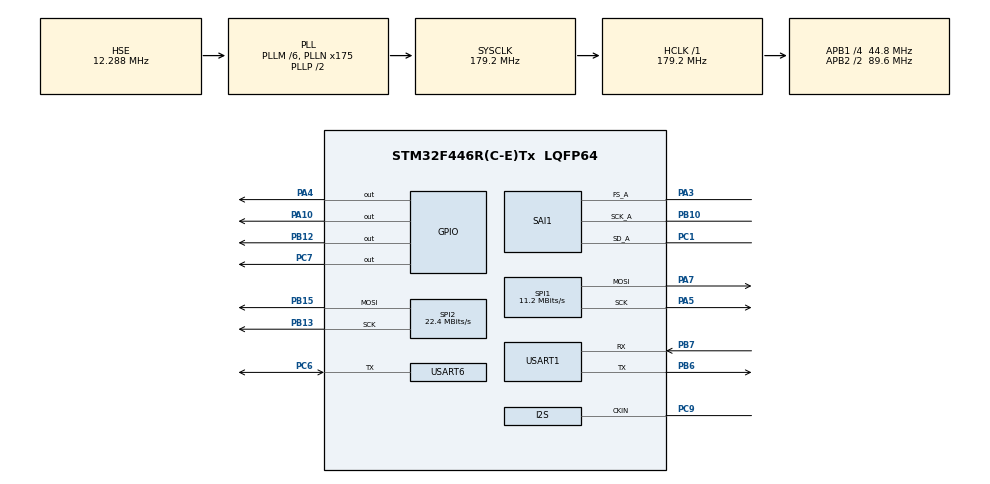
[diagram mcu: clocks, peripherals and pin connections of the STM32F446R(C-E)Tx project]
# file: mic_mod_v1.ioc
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Dma.Request0=SPI2_TX
Dma.Request1=SPI1_TX
Dma.SPI1_TX.1.Direction=DMA_MEMORY_TO_PERIPH
Dma.SPI1_TX.1.FIFOMode=DMA_FIFOMODE_DISABLE
Dma.SPI1_TX.1.Instance=DMA2_Stream3
Dma.SPI1_TX.1.MemDataAlignment=DMA_MDATAALIGN_HALFWORD
Dma.SPI1_TX.1.MemInc=DMA_MINC_ENABLE
Dma.SPI1_TX.1.Mode=DMA_CIRCULAR
Dma.SPI1_TX.1.PeriphDataAlignment=DMA_PDATAALIGN_HALFWORD
Dma.SPI1_TX.1.PeriphInc=DMA_PINC_DISABLE
Dma.SPI1_TX.1.Priority=DMA_PRIORITY_MEDIUM
Dma.SPI2_TX.0.Direction=DMA_MEMORY_TO_PERIPH
Dma.SPI2_TX.0.FIFOMode=DMA_FIFOMODE_DISABLE
Dma.SPI2_TX.0.Instance=DMA1_Stream4
Dma.SPI2_TX.0.MemDataAlignment=DMA_MDATAALIGN_HALFWORD
Dma.SPI2_TX.0.MemInc=DMA_MINC_ENABLE
Dma.SPI2_TX.0.Mode=DMA_CIRCULAR
Dma.SPI2_TX.0.PeriphDataAlignment=DMA_PDATAALIGN_HALFWORD
Dma.SPI2_TX.0.PeriphInc=DMA_PINC_DISABLE
Dma.SPI2_TX.0.Priority=DMA_PRIORITY_MEDIUM
Mcu.Family=STM32F4
Mcu.Name=STM32F446R(C-E)Tx
Mcu.Package=LQFP64
NVIC.DMA1_Stream4_IRQn=true\:0\:0\:false\:false\:true\:false
NVIC.DMA2_Stream3_IRQn=true\:0\:0\:false\:false\:true\:false
NVIC.PriorityGroup=NVIC_PRIORITYGROUP_4
PA10.Signal=GPIO_Output
PA3.Mode=SAI_A_Master
PA3.Signal=SAI1_FS_A
PA4.Signal=GPIO_Output
PA5.Mode=TX_Only_Simplex_Unidirect_Master
PA5.Signal=SPI1_SCK
PA7.Mode=TX_Only_Simplex_Unidirect_Master
PA7.Signal=SPI1_MOSI
PB10.Mode=SAI_A_Master
PB10.Signal=SAI1_SCK_A
PB12.Signal=GPIO_Output
PB13.Mode=TX_Only_Simplex_Unidirect_Master
PB13.Signal=SPI2_SCK
PB15.Mode=TX_Only_Simplex_Unidirect_Master
PB15.Signal=SPI2_MOSI
PB6.Mode=Asynchronous
PB6.Signal=USART1_TX
PB7.Mode=Asynchronous
PB7.Signal=USART1_RX
PC1.Mode=SAI_A_Master
PC1.Signal=SAI1_SD_A
PC6.Mode=Half_duplex(single_wire_mode)
PC6.Signal=USART6_TX
PC7.Signal=GPIO_Output
PC9.Mode=Audio_ClockIn
PC9.Signal=I2S_CKIN
PH0-OSC_IN.Mode=HSE-External-Oscillator
PH0-OSC_IN.Signal=RCC_OSC_IN
PH1-OSC_OUT.Mode=HSE-External-Oscillator
PH1-OSC_OUT.Signal=RCC_OSC_OUT
ProjectManager.HeapSize=0x200
ProjectManager.StackSize=0x400
ProjectManager.TargetToolchain=SW4STM32
RCC.AHBFreq_Value=179200000
RCC.APB1CLKDivider=RCC_HCLK_DIV4
RCC.APB1Freq_Value=44800000
RCC.APB1TimFreq_Value=89600000
RCC.APB2CLKDivider=RCC_HCLK_DIV2
RCC.APB2Freq_Value=89600000
RCC.APB2TimFreq_Value=179200000
RCC.CortexFreq_Value=179200000
RCC.HCLKFreq_Value=179200000
RCC.HSE_VALUE=12288000
RCC.PLLM=6
RCC.PLLN=175
RCC.PLLSAIM=8
RCC.PLLSAIN=169
RCC.PLLSAIQ=8
RCC.PLLSAIQDiv=3
RCC.PLLSourceVirtual=RCC_PLLSOURCE_HSE
RCC.SAIACLockSelection=RCC_SAI1CLKSOURCE_EXT
RCC.SYSCLKFreq_VALUE=179200000
RCC.SYSCLKSource=RCC_SYSCLKSOURCE_PLLCLK
RCC.USBFreq_Value=179200000
RCC.VCOOutputFreq_Value=358400000
SAI1.Instance-SAI_A_Master=SAI$Index_Block_A
SAI1.MClockEnable-SAI_A_Master=SAI_MASTERCLOCK_DISABLE
SAI1.Synchro-SAI_A_Master=SAI_ASYNCHRONOUS
SAI1.VirtualMode-SAI_A_Master=VM_MASTER
SPI1.BaudRatePrescaler=SPI_BAUDRATEPRESCALER_8
SPI1.CalculateBaudRate=11.2 MBits/s
SPI1.DataSize=SPI_DATASIZE_16BIT
SPI1.Direction=SPI_DIRECTION_2LINES
SPI1.Mode=SPI_MODE_MASTER
SPI1.VirtualType=VM_MASTER
SPI2.BaudRatePrescaler=SPI_BAUDRATEPRESCALER_2
SPI2.CalculateBaudRate=22.4 MBits/s
SPI2.DataSize=SPI_DATASIZE_16BIT
SPI2.Direction=SPI_DIRECTION_2LINES
SPI2.Mode=SPI_MODE_MASTER
SPI2.VirtualType=VM_MASTER
USART1.VirtualMode=VM_ASYNC
USART6.VirtualMode=VM_ASYNC
board=mic_mod_v1

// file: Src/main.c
/**
  ******************************************************************************
  * @file           : main.c
  * @brief          : Main program body
  ******************************************************************************
  ** This notice applies to any and all portions of this file
  * that are not between comment pairs USER CODE BEGIN and
  * USER CODE END. Other portions of this file, whether
  * inserted by the user or by software development tools
  * are owned by their respective copyright owners.
  *
  * COPYRIGHT(c) 2018 STMicroelectronics
  *
  * Redistribution and use in source and binary forms, with or without modification,
  * are permitted provided that the following conditions are met:
  *   1. Redistributions of source code must retain the above copyright notice,
  *      this list of conditions and the following disclaimer.
  *   2. Redistributions in binary form must reproduce the above copyright notice,
  *      this list of conditions and the following disclaimer in the documentation
  *      and/or other materials provided with the distribution.
  *   3. Neither the name of STMicroelectronics nor the names of its contributors
  *      may be used to endorse or promote products derived from this software
  *      without specific prior written permission.
  *
  * THIS SOFTWARE IS PROVIDED BY THE COPYRIGHT HOLDERS AND CONTRIBUTORS "AS IS"
  * AND ANY EXPRESS OR IMPLIED WARRANTIES, INCLUDING, BUT NOT LIMITED TO, THE
  * IMPLIED WARRANTIES OF MERCHANTABILITY AND FITNESS FOR A PARTICULAR PURPOSE ARE
  * DISCLAIMED. IN NO EVENT SHALL THE COPYRIGHT HOLDER OR CONTRIBUTORS BE LIABLE
  * FOR ANY DIRECT, INDIRECT, INCIDENTAL, SPECIAL, EXEMPLARY, OR CONSEQUENTIAL
  * DAMAGES (INCLUDING, BUT NOT LIMITED TO, PROCUREMENT OF SUBSTITUTE GOODS OR
  * SERVICES; LOSS OF USE, DATA, OR PROFITS; OR BUSINESS INTERRUPTION) HOWEVER
  * CAUSED AND ON ANY THEORY OF LIABILITY, WHETHER IN CONTRACT, STRICT LIABILITY,
  * OR TORT (INCLUDING NEGLIGENCE OR OTHERWISE) ARISING IN ANY WAY OUT OF THE USE
  * OF THIS SOFTWARE, EVEN IF ADVISED OF THE POSSIBILITY OF SUCH DAMAGE.
  *
  ******************************************************************************
  */
#include "main.h"
#include "stm32f4xx_hal.h"

/* USER CODE BEGIN Includes */

#include "app.h"

/* USER CODE END Includes */

SAI_HandleTypeDef hsai_BlockA1;

SPI_HandleTypeDef hspi1;
SPI_HandleTypeDef hspi2;
DMA_HandleTypeDef hdma_spi1_tx;
DMA_HandleTypeDef hdma_spi2_tx;

UART_HandleTypeDef huart1;
UART_HandleTypeDef huart6;

/* USER CODE BEGIN PV */
/* Private variables ---------------------------------------------------------*/

/* USER CODE END PV */

void SystemClock_Config(void);
static void MX_GPIO_Init(void);
static void MX_DMA_Init(void);
static void MX_SAI1_Init(void);
static void MX_SPI1_Init(void);
static void MX_SPI2_Init(void);
static void MX_USART6_UART_Init(void);
static void MX_USART1_UART_Init(void);

/* USER CODE BEGIN PFP */
/* Private function prototypes -----------------------------------------------*/

/* USER CODE END PFP */

/* USER CODE BEGIN 0 */

#define SZ 8*48

/* USER CODE END 0 */

int main(void)
{

  /* MCU Configuration----------------------------------------------------------*/

  /* Reset of all peripherals, Initializes the Flash interface and the Systick. */
  HAL_Init();

  /* Configure the system clock */
  SystemClock_Config();

  /* Initialize all configured peripherals */
  MX_GPIO_Init();
  MX_DMA_Init();
  MX_SAI1_Init();
  MX_SPI1_Init();
  MX_SPI2_Init();
  MX_USART6_UART_Init();
  MX_USART1_UART_Init();
  /* USER CODE BEGIN 2 */

  //application();
  int16_t pack1[SZ] = {1}, pack2[SZ] = {2};
  int k;

  /* USER CODE END 2 */

  /* Infinite loop */
  /* USER CODE BEGIN WHILE */

  HAL_GPIO_WritePin (GPIOA, GPIO_PIN_4, GPIO_PIN_SET);
  HAL_GPIO_WritePin (GPIOB, GPIO_PIN_12, GPIO_PIN_SET);

  while (1)
  {

    HAL_Delay(1);
    //HAL_GPIO_WritePin(GPIOA, GPIO_PIN_4, GPIO_PIN_SET);
    HAL_GPIO_WritePin(GPIOB, GPIO_PIN_12, GPIO_PIN_SET);

    for (k=0; k<SZ; k++)
    {
      pack1[k]++;
      pack2[k]++;
    }
    //HAL_SPI_Transmit_DMA (&hspi2, (uint8_t *)pack2, sizeof(pack2));
    HAL_SPI_Transmit_DMA (&hspi1, (uint8_t *)pack1, sizeof(pack1));

    HAL_GPIO_WritePin(GPIOB, GPIO_PIN_12, GPIO_PIN_RESET);
    //HAL_GPIO_WritePin(GPIOA, GPIO_PIN_4, GPIO_PIN_RESET);
    //HAL_GPIO_WritePin(GPIOA, GPIO_PIN_4, GPIO_PIN_RESET);
  /* USER CODE END WHILE */

  }

}

void SystemClock_Config(void)
{

  RCC_OscInitTypeDef RCC_OscInitStruct;
  RCC_ClkInitTypeDef RCC_ClkInitStruct;
  RCC_PeriphCLKInitTypeDef PeriphClkInitStruct;

    /**Configure the main internal regulator output voltage
    */
  __HAL_RCC_PWR_CLK_ENABLE();

  __HAL_PWR_VOLTAGESCALING_CONFIG(PWR_REGULATOR_VOLTAGE_SCALE1);

    /**Initializes the CPU, AHB and APB busses clocks
    */
  RCC_OscInitStruct.OscillatorType = RCC_OSCILLATORTYPE_HSE;
  RCC_OscInitStruct.HSEState = RCC_HSE_ON;
  RCC_OscInitStruct.PLL.PLLState = RCC_PLL_ON;
  RCC_OscInitStruct.PLL.PLLSource = RCC_PLLSOURCE_HSE;
  RCC_OscInitStruct.PLL.PLLM = 6;
  RCC_OscInitStruct.PLL.PLLN = 175;
  RCC_OscInitStruct.PLL.PLLP = RCC_PLLP_DIV2;
  RCC_OscInitStruct.PLL.PLLQ = 2;
  RCC_OscInitStruct.PLL.PLLR = 2;
  if (HAL_RCC_OscConfig(&RCC_OscInitStruct) != HAL_OK)
  {
    _Error_Handler(__FILE__, __LINE__);
  }

    /**Activate the Over-Drive mode
    */
  if (HAL_PWREx_EnableOverDrive() != HAL_OK)
  {
    _Error_Handler(__FILE__, __LINE__);
  }

    /**Initializes the CPU, AHB and APB busses clocks
    */
  RCC_ClkInitStruct.ClockType = RCC_CLOCKTYPE_HCLK|RCC_CLOCKTYPE_SYSCLK
                              |RCC_CLOCKTYPE_PCLK1|RCC_CLOCKTYPE_PCLK2;
  RCC_ClkInitStruct.SYSCLKSource = RCC_SYSCLKSOURCE_PLLCLK;
  RCC_ClkInitStruct.AHBCLKDivider = RCC_SYSCLK_DIV1;
  RCC_ClkInitStruct.APB1CLKDivider = RCC_HCLK_DIV4;
  RCC_ClkInitStruct.APB2CLKDivider = RCC_HCLK_DIV2;

  if (HAL_RCC_ClockConfig(&RCC_ClkInitStruct, FLASH_LATENCY_5) != HAL_OK)
  {
    _Error_Handler(__FILE__, __LINE__);
  }

  PeriphClkInitStruct.PeriphClockSelection = RCC_PERIPHCLK_SAI1;
  PeriphClkInitStruct.Sai1ClockSelection = RCC_SAI1CLKSOURCE_EXT;
  if (HAL_RCCEx_PeriphCLKConfig(&PeriphClkInitStruct) != HAL_OK)
  {
    _Error_Handler(__FILE__, __LINE__);
  }

    /**Configure the Systick interrupt time
    */
  HAL_SYSTICK_Config(HAL_RCC_GetHCLKFreq()/1000);

    /**Configure the Systick
    */
  HAL_SYSTICK_CLKSourceConfig(SYSTICK_CLKSOURCE_HCLK);

  /* SysTick_IRQn interrupt configuration */
  HAL_NVIC_SetPriority(SysTick_IRQn, 0, 0);
}

/* SAI1 init function */
static void MX_SAI1_Init(void)
{

  hsai_BlockA1.Instance = SAI1_Block_A;
  hsai_BlockA1.Init.Protocol = SAI_FREE_PROTOCOL;
  hsai_BlockA1.Init.AudioMode = SAI_MODEMASTER_TX;
  hsai_BlockA1.Init.DataSize = SAI_DATASIZE_24;
  hsai_BlockA1.Init.FirstBit = SAI_FIRSTBIT_MSB;
  hsai_BlockA1.Init.ClockStrobing = SAI_CLOCKSTROBING_FALLINGEDGE;
  hsai_BlockA1.Init.Synchro = SAI_ASYNCHRONOUS;
  hsai_BlockA1.Init.OutputDrive = SAI_OUTPUTDRIVE_DISABLE;
  hsai_BlockA1.Init.NoDivider = SAI_MASTERDIVIDER_ENABLE;
  hsai_BlockA1.Init.FIFOThreshold = SAI_FIFOTHRESHOLD_EMPTY;
  hsai_BlockA1.Init.ClockSource = SAI_CLKSOURCE_NA;
  hsai_BlockA1.Init.AudioFrequency = SAI_AUDIO_FREQUENCY_192K;
  hsai_BlockA1.Init.SynchroExt = SAI_SYNCEXT_DISABLE;
  hsai_BlockA1.Init.MonoStereoMode = SAI_STEREOMODE;
  hsai_BlockA1.Init.CompandingMode = SAI_NOCOMPANDING;
  hsai_BlockA1.Init.TriState = SAI_OUTPUT_NOTRELEASED;
  hsai_BlockA1.FrameInit.FrameLength = 8;
  hsai_BlockA1.FrameInit.ActiveFrameLength = 1;
  hsai_BlockA1.FrameInit.FSDefinition = SAI_FS_STARTFRAME;
  hsai_BlockA1.FrameInit.FSPolarity = SAI_FS_ACTIVE_LOW;
  hsai_BlockA1.FrameInit.FSOffset = SAI_FS_FIRSTBIT;
  hsai_BlockA1.SlotInit.FirstBitOffset = 0;
  hsai_BlockA1.SlotInit.SlotSize = SAI_SLOTSIZE_DATASIZE;
  hsai_BlockA1.SlotInit.SlotNumber = 1;
  hsai_BlockA1.SlotInit.SlotActive = 0x00000000;
  if (HAL_SAI_Init(&hsai_BlockA1) != HAL_OK)
  {
    _Error_Handler(__FILE__, __LINE__);
  }

}

/* SPI1 init function */
static void MX_SPI1_Init(void)
{

  /* SPI1 parameter configuration*/
  hspi1.Instance = SPI1;
  hspi1.Init.Mode = SPI_MODE_MASTER;
  hspi1.Init.Direction = SPI_DIRECTION_2LINES;
  hspi1.Init.DataSize = SPI_DATASIZE_16BIT;
  hspi1.Init.CLKPolarity = SPI_POLARITY_LOW;
  hspi1.Init.CLKPhase = SPI_PHASE_1EDGE;
  hspi1.Init.NSS = SPI_NSS_SOFT;
  hspi1.Init.BaudRatePrescaler = SPI_BAUDRATEPRESCALER_8;
  hspi1.Init.FirstBit = SPI_FIRSTBIT_MSB;
  hspi1.Init.TIMode = SPI_TIMODE_DISABLE;
  hspi1.Init.CRCCalculation = SPI_CRCCALCULATION_DISABLE;
  hspi1.Init.CRCPolynomial = 10;
  if (HAL_SPI_Init(&hspi1) != HAL_OK)
  {
    _Error_Handler(__FILE__, __LINE__);
  }

}

/* SPI2 init function */
static void MX_SPI2_Init(void)
{

  /* SPI2 parameter configuration*/
  hspi2.Instance = SPI2;
  hspi2.Init.Mode = SPI_MODE_MASTER;
  hspi2.Init.Direction = SPI_DIRECTION_2LINES;
  hspi2.Init.DataSize = SPI_DATASIZE_16BIT;
  hspi2.Init.CLKPolarity = SPI_POLARITY_LOW;
  hspi2.Init.CLKPhase = SPI_PHASE_1EDGE;
  hspi2.Init.NSS = SPI_NSS_SOFT;
  hspi2.Init.BaudRatePrescaler = SPI_BAUDRATEPRESCALER_2;
  hspi2.Init.FirstBit = SPI_FIRSTBIT_MSB;
  hspi2.Init.TIMode = SPI_TIMODE_DISABLE;
  hspi2.Init.CRCCalculation = SPI_CRCCALCULATION_DISABLE;
  hspi2.Init.CRCPolynomial = 10;
  if (HAL_SPI_Init(&hspi2) != HAL_OK)
  {
    _Error_Handler(__FILE__, __LINE__);
  }

}

/* USART1 init function */
static void MX_USART1_UART_Init(void)
{

  huart1.Instance = USART1;
  huart1.Init.BaudRate = 115200;
  huart1.Init.WordLength = UART_WORDLENGTH_8B;
  huart1.Init.StopBits = UART_STOPBITS_1;
  huart1.Init.Parity = UART_PARITY_NONE;
  huart1.Init.Mode = UART_MODE_TX_RX;
  huart1.Init.HwFlowCtl = UART_HWCONTROL_NONE;
  huart1.Init.OverSampling = UART_OVERSAMPLING_16;
  if (HAL_UART_Init(&huart1) != HAL_OK)
  {
    _Error_Handler(__FILE__, __LINE__);
  }

}

/* USART6 init function */
static void MX_USART6_UART_Init(void)
{

  huart6.Instance = USART6;
  huart6.Init.BaudRate = 115200;
  huart6.Init.WordLength = UART_WORDLENGTH_8B;
  huart6.Init.StopBits = UART_STOPBITS_1;
  huart6.Init.Parity = UART_PARITY_NONE;
  huart6.Init.Mode = UART_MODE_TX_RX;
  huart6.Init.HwFlowCtl = UART_HWCONTROL_NONE;
  huart6.Init.OverSampling = UART_OVERSAMPLING_16;
  if (HAL_HalfDuplex_Init(&huart6) != HAL_OK)
  {
    _Error_Handler(__FILE__, __LINE__);
  }

}

static void MX_DMA_Init(void)
{
  /* DMA controller clock enable */
  __HAL_RCC_DMA1_CLK_ENABLE();
  __HAL_RCC_DMA2_CLK_ENABLE();

  /* DMA interrupt init */
  /* DMA1_Stream4_IRQn interrupt configuration */
  HAL_NVIC_SetPriority(DMA1_Stream4_IRQn, 0, 0);
  HAL_NVIC_EnableIRQ(DMA1_Stream4_IRQn);
  /* DMA2_Stream3_IRQn interrupt configuration */
  HAL_NVIC_SetPriority(DMA2_Stream3_IRQn, 0, 0);
  HAL_NVIC_EnableIRQ(DMA2_Stream3_IRQn);

}

/** Configure pins as
        * Analog
        * Input
        * Output
        * EVENT_OUT
        * EXTI
     PC9   ------> I2S_CKIN
*/
static void MX_GPIO_Init(void)
{

  GPIO_InitTypeDef GPIO_InitStruct;

  /* GPIO Ports Clock Enable */
  __HAL_RCC_GPIOH_CLK_ENABLE();
  __HAL_RCC_GPIOC_CLK_ENABLE();
  __HAL_RCC_GPIOA_CLK_ENABLE();
  __HAL_RCC_GPIOB_CLK_ENABLE();

  /*Configure GPIO pin Output Level */
  HAL_GPIO_WritePin(GPIOA, GPIO_PIN_4|GPIO_PIN_10, GPIO_PIN_RESET);

  /*Configure GPIO pin Output Level */
  HAL_GPIO_WritePin(GPIOB, GPIO_PIN_12, GPIO_PIN_RESET);

  /*Configure GPIO pin Output Level */
  HAL_GPIO_WritePin(GPIOC, GPIO_PIN_7, GPIO_PIN_RESET);

  /*Configure GPIO pins : PA4 PA10 */
  GPIO_InitStruct.Pin = GPIO_PIN_4|GPIO_PIN_10;
  GPIO_InitStruct.Mode = GPIO_MODE_OUTPUT_PP;
  GPIO_InitStruct.Pull = GPIO_NOPULL;
  GPIO_InitStruct.Speed = GPIO_SPEED_FREQ_LOW;
  HAL_GPIO_Init(GPIOA, &GPIO_InitStruct);

  /*Configure GPIO pin : PB12 */
  GPIO_InitStruct.Pin = GPIO_PIN_12;
  GPIO_InitStruct.Mode = GPIO_MODE_OUTPUT_PP;
  GPIO_InitStruct.Pull = GPIO_NOPULL;
  GPIO_InitStruct.Speed = GPIO_SPEED_FREQ_LOW;
  HAL_GPIO_Init(GPIOB, &GPIO_InitStruct);

  /*Configure GPIO pin : PC7 */
  GPIO_InitStruct.Pin = GPIO_PIN_7;
  GPIO_InitStruct.Mode = GPIO_MODE_OUTPUT_PP;
  GPIO_InitStruct.Pull = GPIO_NOPULL;
  GPIO_InitStruct.Speed = GPIO_SPEED_FREQ_LOW;
  HAL_GPIO_Init(GPIOC, &GPIO_InitStruct);

  /*Configure GPIO pin : PC9 */
  GPIO_InitStruct.Pin = GPIO_PIN_9;
  GPIO_InitStruct.Mode = GPIO_MODE_AF_PP;
  GPIO_InitStruct.Pull = GPIO_NOPULL;
  GPIO_InitStruct.Speed = GPIO_SPEED_FREQ_LOW;
  GPIO_InitStruct.Alternate = GPIO_AF5_SPI1;
  HAL_GPIO_Init(GPIOC, &GPIO_InitStruct);

}

void _Error_Handler(char *file, int line)
{
  while(1)
  {
  }
}

/************************ (C) COPYRIGHT STMicroelectronics *****END OF FILE****/
